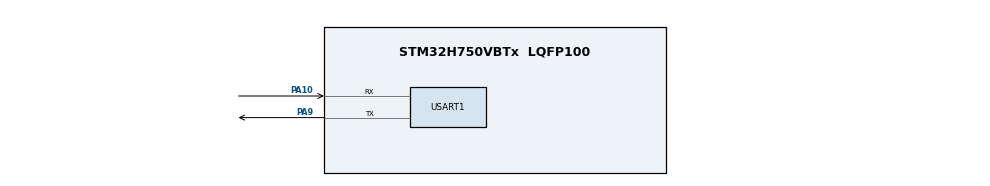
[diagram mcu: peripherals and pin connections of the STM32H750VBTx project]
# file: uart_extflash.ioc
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CORTEX_M7.default_mode_Activation=0
Mcu.Family=STM32H7
Mcu.Name=STM32H750VBTx
Mcu.Package=LQFP100
NVIC.PriorityGroup=NVIC_PRIORITYGROUP_4
PA10.Mode=Asynchronous
PA10.Signal=USART1_RX
PA9.Mode=Asynchronous
PA9.Signal=USART1_TX
ProjectManager.HeapSize=0x200
ProjectManager.StackSize=0x400
ProjectManager.TargetToolchain=MDK-ARM V5.32
RCC.ADCFreq_Value=129000000
RCC.APB1Freq_Value=32000000
RCC.APB2Freq_Value=32000000
RCC.APB3Freq_Value=32000000
RCC.APB4Freq_Value=32000000
RCC.CortexFreq_Value=64000000
RCC.D1PPRE=RCC_APB3_DIV2
RCC.D2PPRE1=RCC_APB1_DIV2
RCC.D2PPRE2=RCC_APB2_DIV2
RCC.D3PPRE=RCC_APB4_DIV2
RCC.HCLKFreq_Value=64000000
RCC.SYSCLKFreq_VALUE=64000000
RCC.USBFreq_Value=129000000
USART1.VirtualMode-Asynchronous=VM_ASYNC
board=custom

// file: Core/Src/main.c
/* USER CODE BEGIN Header */
/**
  ******************************************************************************
  * @file           : main.c
  * @brief          : Main program body
  ******************************************************************************
  * @attention
  *
  * Copyright (c) 2023 STMicroelectronics.
  * All rights reserved.
  *
  * This software is licensed under terms that can be found in the LICENSE file
  * in the root directory of this software component.
  * If no LICENSE file comes with this software, it is provided AS-IS.
  *
  ******************************************************************************
  */
/* USER CODE END Header */
#include "main.h"
#include "usart.h"
#include "gpio.h"

/* USER CODE BEGIN Includes */
#include <stdio.h>
#include <string.h>
#include "bsp_rgb.h"
/* USER CODE END Includes */

void SystemClock_Config(void);
/* USER CODE BEGIN PFP */
static void App_ProcessCommands(void);
/* USER CODE END PFP */

int main(void)
{
  /* USER CODE BEGIN 1 */
  SCB->VTOR = 0x90000000UL; /* 1. Relocate vector table to QSPI XIP before any interrupts */
  __enable_irq();            /* 2. Re-enable global interrupts disabled by bootloader */
  /* USER CODE END 1 */

  /* MCU Configuration--------------------------------------------------------*/

  /* Reset of all peripherals, Initializes the Flash interface and the Systick. */
  HAL_Init();

  /* Configure the system clock */
  SystemClock_Config();

  /* Initialize all configured peripherals */
  MX_GPIO_Init();
  MX_USART1_UART_Init();
  /* USER CODE BEGIN 2 */
  SystemCoreClockUpdate();
  BSP_RGB_Init();

  printf("\r\n");
  printf("====================================================\r\n");
  printf("  *** STM32H750VBT6 External Flash App Running ***  \r\n");
  printf("====================================================\r\n");
  printf(" [Build Time]   : %s %s\r\n", __DATE__, __TIME__);
  printf(" [System Clock] : %lu MHz\r\n", (unsigned long)(SystemCoreClock / 1000000));
  printf(" [Execution PC] : 0x%08lX (QSPI XIP Region)\r\n", (unsigned long)&main);
  printf(" [Vector VTOR]  : 0x%08lX\r\n", (unsigned long)SCB->VTOR);
  printf(" [Current MSP]  : 0x%08lX (AXI SRAM)\r\n", (unsigned long)__get_MSP());
  printf(" [MCU 96-bit UID]: %08lX-%08lX-%08lX\r\n",
         (unsigned long)HAL_GetUIDw0(),
         (unsigned long)HAL_GetUIDw1(),
         (unsigned long)HAL_GetUIDw2());
  printf(" [Target Flash] : Winbond W25Q64JVSIQ (8MB, Quad-SPI)\r\n");
  printf(" [Onboard RGB]  : PA1 (R), PC3 (G), PC1 (B)\r\n");
  printf("====================================================\r\n\r\n");

  /* Color sequence for RGB animation */
  const RGB_Color_t color_sequence[] = {
      RGB_COLOR_RED,
      RGB_COLOR_GREEN,
      RGB_COLOR_BLUE,
      RGB_COLOR_YELLOW,
      RGB_COLOR_PURPLE,
      RGB_COLOR_CYAN,
      RGB_COLOR_WHITE,
      RGB_COLOR_OFF
  };
  const uint32_t color_count = sizeof(color_sequence) / sizeof(color_sequence[0]);
  uint32_t step = 0;
  /* USER CODE END 2 */

  /* Infinite loop */
  /* USER CODE BEGIN WHILE */
  printf("{\"type\":\"app_status\",\"app\":\"uart_extflash\",\"slot\":0,\"version\":\"v1.0.0\",\"tick\":%lu,\"clock_mhz\":%lu}\r\n",
         (unsigned long)HAL_GetTick(),
         (unsigned long)(SystemCoreClock / 1000000));

  uint32_t last_alive_tick = HAL_GetTick();

  while (1)
  {
    /* 实时处理串口指令 (极速响应 jump_boot) */
    App_ProcessCommands();

    /* 周期性状态与 RGB 呼吸 */
    if (HAL_GetTick() - last_alive_tick >= 1000)
    {
      last_alive_tick = HAL_GetTick();
      RGB_Color_t current_color = color_sequence[step % color_count];
      BSP_RGB_SetColor(current_color);

      printf("[App Alive] Tick: %8lu ms | Step: %-2lu | RGB: %s\r\n",
             (unsigned long)HAL_GetTick(),
             (unsigned long)step,
             BSP_RGB_GetColorName(current_color));
      step++;
    }
    /* USER CODE END WHILE */

  }
}

void SystemClock_Config(void)
{
  RCC_OscInitTypeDef RCC_OscInitStruct = {0};
  RCC_ClkInitTypeDef RCC_ClkInitStruct = {0};

  /** Supply configuration update enable
  */
  HAL_PWREx_ConfigSupply(PWR_LDO_SUPPLY);

  /** Configure the main internal regulator output voltage
  */
  __HAL_PWR_VOLTAGESCALING_CONFIG(PWR_REGULATOR_VOLTAGE_SCALE3);

  while(!__HAL_PWR_GET_FLAG(PWR_FLAG_VOSRDY)) {}

  /** Initializes the RCC Oscillators according to the specified parameters
  * in the RCC_OscInitTypeDef structure.
  */
  RCC_OscInitStruct.OscillatorType = RCC_OSCILLATORTYPE_HSI;
  RCC_OscInitStruct.HSIState = RCC_HSI_DIV1;
  RCC_OscInitStruct.HSICalibrationValue = RCC_HSICALIBRATION_DEFAULT;
  RCC_OscInitStruct.PLL.PLLState = RCC_PLL_NONE;
  if (HAL_RCC_OscConfig(&RCC_OscInitStruct) != HAL_OK)
  {
    Error_Handler();
  }

  /** Initializes the CPU, AHB and APB buses clocks
  */
  RCC_ClkInitStruct.ClockType = RCC_CLOCKTYPE_HCLK|RCC_CLOCKTYPE_SYSCLK
                              |RCC_CLOCKTYPE_PCLK1|RCC_CLOCKTYPE_PCLK2
                              |RCC_CLOCKTYPE_D3PCLK1|RCC_CLOCKTYPE_D1PCLK1;
  RCC_ClkInitStruct.SYSCLKSource = RCC_SYSCLKSOURCE_HSI;
  RCC_ClkInitStruct.SYSCLKDivider = RCC_SYSCLK_DIV1;
  RCC_ClkInitStruct.AHBCLKDivider = RCC_HCLK_DIV1;
  RCC_ClkInitStruct.APB3CLKDivider = RCC_APB3_DIV2;
  RCC_ClkInitStruct.APB1CLKDivider = RCC_APB1_DIV2;
  RCC_ClkInitStruct.APB2CLKDivider = RCC_APB2_DIV2;
  RCC_ClkInitStruct.APB4CLKDivider = RCC_APB4_DIV2;

  if (HAL_RCC_ClockConfig(&RCC_ClkInitStruct, FLASH_LATENCY_1) != HAL_OK)
  {
    Error_Handler();
  }
}

/* USER CODE BEGIN 4 */
static void App_ProcessCommands(void)
{
  static char cmd_buf[64];
  static uint8_t cmd_idx = 0;

  /* 清理串口溢出与帧错误标志 */
  if (USART1->ISR & (USART_ISR_ORE | USART_ISR_FE | USART_ISR_NE))
  {
    USART1->ICR = USART_ICR_ORECF | USART_ICR_FECF | USART_ICR_NECF;
  }

  while (USART1->ISR & USART_ISR_RXNE_RXFNE)
  {
    char ch = (char)(USART1->RDR & 0xFF);

    if (cmd_idx < sizeof(cmd_buf) - 1)
    {
      cmd_buf[cmd_idx++] = ch;
      cmd_buf[cmd_idx] = '\0';
    }
    else
    {
      cmd_idx = 0;
      cmd_buf[0] = '\0';
    }

    /* 1. 实时多关键字匹配：只要收到 jump_boot/bootloader/reset 立即复位进入 Bootloader */
    if (strstr(cmd_buf, "jump_boot") != NULL ||
        strstr(cmd_buf, "bootloader") != NULL ||
        strstr(cmd_buf, "reset") != NULL)
    {
      printf("\r\n[APP] Received jump command! Resetting MCU to Bootloader in 20ms...\r\n");
      BSP_RGB_SetColor(RGB_COLOR_RED);
      HAL_Delay(20);
      NVIC_SystemReset();
    }

    /* 2. 换行时解析状态与帮助 */
    if (ch == '\r' || ch == '\n')
    {
      if (strstr(cmd_buf, "status") != NULL ||
          strstr(cmd_buf, "whoami") != NULL ||
          strstr(cmd_buf, "json") != NULL ||
          strstr(cmd_buf, "info") != NULL)
      {
        printf("{\"type\":\"app_status\",\"app\":\"uart_extflash\",\"slot\":0,\"version\":\"v1.0.0\",\"tick\":%lu,\"clock_mhz\":%lu}\r\n",
               (unsigned long)HAL_GetTick(),
               (unsigned long)(SystemCoreClock / 1000000));
      }
      else if (strstr(cmd_buf, "help") != NULL)
      {
        printf("\r\n[APP CLI] Available commands: 'jump_boot' (enter bootloader), 'status' (get app status), 'help'\r\n");
      }
      cmd_idx = 0;
      cmd_buf[0] = '\0';
    }
  }
}
/* USER CODE END 4 */

void Error_Handler(void)
{
  __disable_irq();
  while (1)
  {
  }
}
